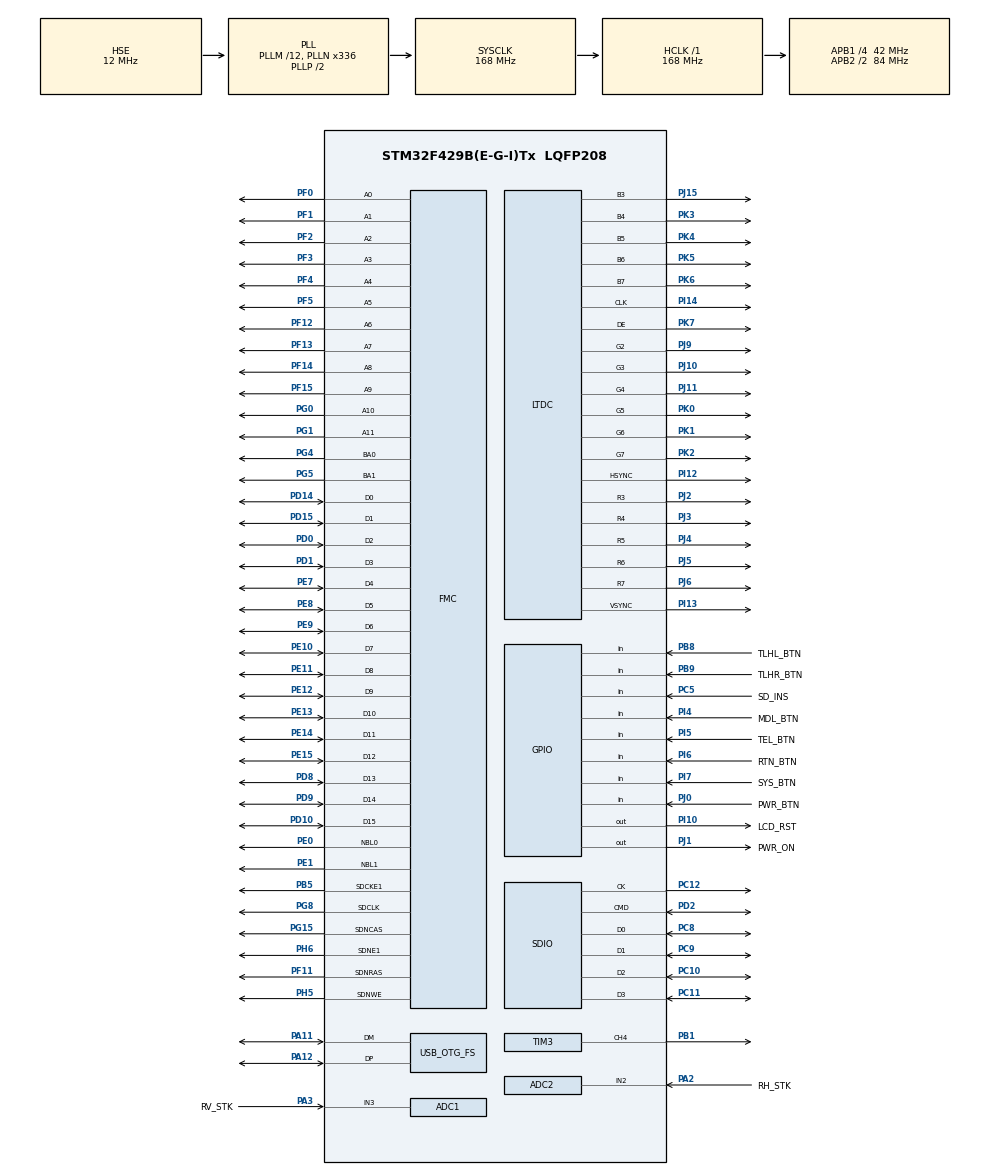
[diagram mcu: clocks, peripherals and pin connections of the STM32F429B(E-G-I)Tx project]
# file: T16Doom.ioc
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ADC1.Channel-0\#ChannelRegularConversion=ADC_CHANNEL_3
ADC1.NbrOfConversion=1
ADC1.NbrOfConversionFlag=1
ADC1.Rank-0\#ChannelRegularConversion=1
ADC1.SamplingTime-0\#ChannelRegularConversion=ADC_SAMPLETIME_3CYCLES
ADC1.master=1
ADC2.Channel-0\#ChannelRegularConversion=ADC_CHANNEL_2
ADC2.NbrOfConversionFlag=1
ADC2.Rank-0\#ChannelRegularConversion=1
ADC2.SamplingTime-0\#ChannelRegularConversion=ADC_SAMPLETIME_3CYCLES
Dma.Request0=SDIO_RX
Dma.Request1=SDIO_TX
Dma.SDIO_RX.0.Direction=DMA_PERIPH_TO_MEMORY
Dma.SDIO_RX.0.FIFOMode=DMA_FIFOMODE_ENABLE
Dma.SDIO_RX.0.FIFOThreshold=DMA_FIFO_THRESHOLD_FULL
Dma.SDIO_RX.0.Instance=DMA2_Stream3
Dma.SDIO_RX.0.MemBurst=DMA_MBURST_INC4
Dma.SDIO_RX.0.MemDataAlignment=DMA_MDATAALIGN_WORD
Dma.SDIO_RX.0.MemInc=DMA_MINC_ENABLE
Dma.SDIO_RX.0.Mode=DMA_PFCTRL
Dma.SDIO_RX.0.PeriphBurst=DMA_PBURST_INC4
Dma.SDIO_RX.0.PeriphDataAlignment=DMA_PDATAALIGN_WORD
Dma.SDIO_RX.0.PeriphInc=DMA_PINC_DISABLE
Dma.SDIO_RX.0.Priority=DMA_PRIORITY_LOW
Dma.SDIO_TX.1.Direction=DMA_MEMORY_TO_PERIPH
Dma.SDIO_TX.1.FIFOMode=DMA_FIFOMODE_ENABLE
Dma.SDIO_TX.1.FIFOThreshold=DMA_FIFO_THRESHOLD_FULL
Dma.SDIO_TX.1.Instance=DMA2_Stream6
Dma.SDIO_TX.1.MemBurst=DMA_MBURST_INC4
Dma.SDIO_TX.1.MemDataAlignment=DMA_MDATAALIGN_WORD
Dma.SDIO_TX.1.MemInc=DMA_MINC_ENABLE
Dma.SDIO_TX.1.Mode=DMA_PFCTRL
Dma.SDIO_TX.1.PeriphBurst=DMA_PBURST_INC4
Dma.SDIO_TX.1.PeriphDataAlignment=DMA_PDATAALIGN_WORD
Dma.SDIO_TX.1.PeriphInc=DMA_PINC_DISABLE
Dma.SDIO_TX.1.Priority=DMA_PRIORITY_LOW
FATFS.BSP.number=1
FATFS.USE_DMA_CODE_SD=1
FATFS._MAX_SS=4096
FATFS0.BSP.STBoard=false
FATFS0.BSP.api=Unknown
FATFS0.BSP.i2caddr=0
FATFS0.BSP.instance=PC5
FATFS0.BSP.ip=GPIO
FATFS0.BSP.mode=Input
FATFS0.BSP.name=Detect_SDIO
FATFS0.BSP.solution=PC5
FMC.CASLatency1=FMC_SDRAM_CAS_LATENCY_3
FMC.ExitSelfRefreshDelay1=7
FMC.LoadToActiveDelay1=2
FMC.RCDDelay1=2
FMC.RPDelay1=2
FMC.RPDelay2=2
FMC.RowCycleDelay1=7
FMC.RowCycleDelay2=7
FMC.SDClockPeriod1=FMC_SDRAM_CLOCK_PERIOD_2
FMC.SDClockPeriod2=FMC_SDRAM_CLOCK_PERIOD_2
FMC.SelfRefreshTime1=4
FMC.WriteRecoveryTime1=3
LTDC.ActiveH=272
LTDC.ActiveW=480
LTDC.Alpha_L0=255
LTDC.Alpha_L1=255
LTDC.BlendingFactor1_L0=LTDC_BLENDING_FACTOR1_CA
LTDC.BlendingFactor1_L1=LTDC_BLENDING_FACTOR1_CA
LTDC.BlendingFactor2_L0=LTDC_BLENDING_FACTOR2_CA
LTDC.BlendingFactor2_L1=LTDC_BLENDING_FACTOR2_CA
LTDC.FBStartAdress_L0=(uint32_t) LCDFrameBuffer
LTDC.HBP=40
LTDC.HFP=3
LTDC.HSync=3
LTDC.ImageHeight_L0=272
LTDC.ImageHeight_L1=272
LTDC.ImageWidth_L0=480
LTDC.ImageWidth_L1=480
LTDC.Layers=0
LTDC.PCPolarity=LTDC_PCPOLARITY_IIPC
LTDC.PixelFormat_L0=LTDC_PIXEL_FORMAT_RGB565
LTDC.VBP=2
LTDC.VFP=2
LTDC.VSync=11
LTDC.WindowX0_L0=0
LTDC.WindowX0_L1=0
LTDC.WindowX1_L0=480
LTDC.WindowX1_L1=480
LTDC.WindowY0_L0=0
LTDC.WindowY0_L1=0
LTDC.WindowY1_L0=272
LTDC.WindowY1_L1=272
Mcu.Family=STM32F4
Mcu.Name=STM32F429B(E-G-I)Tx
Mcu.Package=LQFP208
NVIC.DMA2_Stream3_IRQn=true\:0\:0\:false\:false\:true\:false\:true
NVIC.DMA2_Stream6_IRQn=true\:0\:0\:false\:false\:true\:false\:true
NVIC.OTG_FS_IRQn=true\:0\:0\:false\:false\:true\:false\:true
NVIC.PriorityGroup=NVIC_PRIORITYGROUP_4
NVIC.SDIO_IRQn=true\:0\:0\:false\:false\:true\:true\:true
PA11.Mode=Device_Only
PA11.Signal=USB_OTG_FS_DM
PA12.Mode=Device_Only
PA12.Signal=USB_OTG_FS_DP
PA2.GPIO_Label=RH_STK
PA2.Signal=SharedAnalog_PA2
PA3.GPIO_Label=RV_STK
PA3.Signal=SharedAnalog_PA3
PB1.Signal=S_TIM3_CH4
PB5.Mode=SdramChipSelect2_1
PB5.Signal=FMC_SDCKE1
PB8.GPIO_Label=TLHL_BTN
PB8.GPIO_PuPd=GPIO_PULLUP
PB8.Signal=GPIO_Input
PB9.GPIO_Label=TLHR_BTN
PB9.GPIO_PuPd=GPIO_PULLUP
PB9.Signal=GPIO_Input
PC10.GPIO_PuPd=GPIO_PULLUP
PC10.Mode=SD_4_bits_Wide_bus
PC10.Signal=SDIO_D2
PC11.GPIO_PuPd=GPIO_PULLUP
PC11.Mode=SD_4_bits_Wide_bus
PC11.Signal=SDIO_D3
PC12.Mode=SD_4_bits_Wide_bus
PC12.Signal=SDIO_CK
PC14/OSC32_IN.Mode=LSE-External-Oscillator
PC14/OSC32_IN.Signal=RCC_OSC32_IN
PC15/OSC32_OUT.Mode=LSE-External-Oscillator
PC15/OSC32_OUT.Signal=RCC_OSC32_OUT
PC5.GPIO_Label=SD_INS
PC5.Signal=GPIO_Input
PC8.GPIO_PuPd=GPIO_PULLUP
PC8.Mode=SD_4_bits_Wide_bus
PC8.Signal=SDIO_D0
PC9.GPIO_PuPd=GPIO_PULLUP
PC9.Mode=SD_4_bits_Wide_bus
PC9.Signal=SDIO_D1
PD0.Signal=FMC_D2_DA2
PD1.Signal=FMC_D3_DA3
PD10.Signal=FMC_D15_DA15
PD14.Signal=FMC_D0_DA0
PD15.Signal=FMC_D1_DA1
PD2.GPIO_PuPd=GPIO_PULLUP
PD2.Mode=SD_4_bits_Wide_bus
PD2.Signal=SDIO_CMD
PD8.Signal=FMC_D13_DA13
PD9.Signal=FMC_D14_DA14
PE0.Signal=FMC_NBL0
PE1.Signal=FMC_NBL1
PE10.Signal=FMC_D7_DA7
PE11.Signal=FMC_D8_DA8
PE12.Signal=FMC_D9_DA9
PE13.Signal=FMC_D10_DA10
PE14.Signal=FMC_D11_DA11
PE15.Signal=FMC_D12_DA12
PE7.Signal=FMC_D4_DA4
PE8.Signal=FMC_D5_DA5
PE9.Signal=FMC_D6_DA6
PF0.Signal=FMC_A0
PF1.Signal=FMC_A1
PF11.Signal=FMC_SDNRAS
PF12.Signal=FMC_A6
PF13.Signal=FMC_A7
PF14.Signal=FMC_A8
PF15.Signal=FMC_A9
PF2.Signal=FMC_A2
PF3.Signal=FMC_A3
PF4.Signal=FMC_A4
PF5.Signal=FMC_A5
PG0.Signal=FMC_A10
PG1.Signal=FMC_A11
PG15.Signal=FMC_SDNCAS
PG4.Signal=FMC_A14_BA0
PG5.Signal=FMC_A15_BA1
PG8.Signal=FMC_SDCLK
PH0/OSC_IN.Mode=HSE-External-Oscillator
PH0/OSC_IN.Signal=RCC_OSC_IN
PH1/OSC_OUT.Mode=HSE-External-Oscillator
PH1/OSC_OUT.Signal=RCC_OSC_OUT
PH5.Signal=FMC_SDNWE
PH6.Mode=SdramChipSelect2_1
PH6.Signal=FMC_SDNE1
PI10.GPIO_Label=LCD_RST
PI10.Signal=GPIO_Output
PI12.GPIO_Speed=GPIO_SPEED_FREQ_LOW
PI12.Mode=RGB565
PI12.Signal=LTDC_HSYNC
PI13.GPIO_Speed=GPIO_SPEED_FREQ_LOW
PI13.Mode=RGB565
PI13.Signal=LTDC_VSYNC
PI14.GPIO_Speed=GPIO_SPEED_FREQ_LOW
PI14.Mode=RGB565
PI14.Signal=LTDC_CLK
PI4.GPIO_Label=MDL_BTN
PI4.GPIO_PuPd=GPIO_PULLUP
PI4.Signal=GPIO_Input
PI5.GPIO_Label=TEL_BTN
PI5.GPIO_PuPd=GPIO_PULLUP
PI5.Signal=GPIO_Input
PI6.GPIO_Label=RTN_BTN
PI6.GPIO_PuPd=GPIO_PULLUP
PI6.Signal=GPIO_Input
PI7.GPIO_Label=SYS_BTN
PI7.GPIO_PuPd=GPIO_PULLUP
PI7.Signal=GPIO_Input
PJ0.GPIO_Label=PWR_BTN
PJ0.Signal=GPIO_Input
PJ1.GPIO_Label=PWR_ON
PJ1.Signal=GPIO_Output
PJ10.GPIO_Speed=GPIO_SPEED_FREQ_LOW
PJ10.Mode=RGB565
PJ10.Signal=LTDC_G3
PJ11.GPIO_Speed=GPIO_SPEED_FREQ_LOW
PJ11.Mode=RGB565
PJ11.Signal=LTDC_G4
PJ15.GPIO_Speed=GPIO_SPEED_FREQ_LOW
PJ15.Mode=RGB565
PJ15.Signal=LTDC_B3
PJ2.GPIO_Speed=GPIO_SPEED_FREQ_LOW
PJ2.Mode=RGB565
PJ2.Signal=LTDC_R3
PJ3.GPIO_Speed=GPIO_SPEED_FREQ_LOW
PJ3.Mode=RGB565
PJ3.Signal=LTDC_R4
PJ4.GPIO_Speed=GPIO_SPEED_FREQ_LOW
PJ4.Mode=RGB565
PJ4.Signal=LTDC_R5
PJ5.GPIO_Speed=GPIO_SPEED_FREQ_LOW
PJ5.Mode=RGB565
PJ5.Signal=LTDC_R6
PJ6.GPIO_Speed=GPIO_SPEED_FREQ_LOW
PJ6.Mode=RGB565
PJ6.Signal=LTDC_R7
PJ9.GPIO_Speed=GPIO_SPEED_FREQ_LOW
PJ9.Mode=RGB565
PJ9.Signal=LTDC_G2
PK0.GPIO_Speed=GPIO_SPEED_FREQ_LOW
PK0.Mode=RGB565
PK0.Signal=LTDC_G5
PK1.GPIO_Speed=GPIO_SPEED_FREQ_LOW
PK1.Mode=RGB565
PK1.Signal=LTDC_G6
PK2.GPIO_Speed=GPIO_SPEED_FREQ_LOW
PK2.Mode=RGB565
PK2.Signal=LTDC_G7
PK3.GPIO_Speed=GPIO_SPEED_FREQ_LOW
PK3.Mode=RGB565
PK3.Signal=LTDC_B4
PK4.GPIO_Speed=GPIO_SPEED_FREQ_LOW
PK4.Mode=RGB565
PK4.Signal=LTDC_B5
PK5.GPIO_Speed=GPIO_SPEED_FREQ_LOW
PK5.Mode=RGB565
PK5.Signal=LTDC_B6
PK6.GPIO_Speed=GPIO_SPEED_FREQ_LOW
PK6.Mode=RGB565
PK6.Signal=LTDC_B7
PK7.GPIO_Speed=GPIO_SPEED_FREQ_LOW
PK7.Mode=RGB565
PK7.Signal=LTDC_DE
ProjectManager.HeapSize=0x200
ProjectManager.StackSize=0x400
ProjectManager.TargetToolchain=Makefile
RCC.48MHZClocksFreq_Value=48000000
RCC.AHBFreq_Value=168000000
RCC.APB1CLKDivider=RCC_HCLK_DIV4
RCC.APB1Freq_Value=42000000
RCC.APB1TimFreq_Value=84000000
RCC.APB2CLKDivider=RCC_HCLK_DIV2
RCC.APB2Freq_Value=84000000
RCC.APB2TimFreq_Value=168000000
RCC.CortexFreq_Value=168000000
RCC.HCLKFreq_Value=168000000
RCC.HSE_VALUE=12000000
RCC.HSI_VALUE=16000000
RCC.PLLM=12
RCC.PLLN=336
RCC.PLLQ=7
RCC.PLLSAIDivR=RCC_PLLSAIDIVR_4
RCC.PLLSAIN=192
RCC.PLLSAIR=3
RCC.SYSCLKFreq_VALUE=168000000
RCC.SYSCLKSource=RCC_SYSCLKSOURCE_PLLCLK
RCC.VCOOutputFreq_Value=336000000
SDIO.ClockDiv=0
SH.FMC_A0.0=FMC_A0,12b-sda1
SH.FMC_A1.0=FMC_A1,12b-sda1
SH.FMC_A10.0=FMC_A10,12b-sda1
SH.FMC_A11.0=FMC_A11,12b-sda1
SH.FMC_A14_BA0.0=FMC_BA0,FourSdramBanks1
SH.FMC_A15_BA1.0=FMC_BA1,FourSdramBanks1
SH.FMC_A2.0=FMC_A2,12b-sda1
SH.FMC_A3.0=FMC_A3,12b-sda1
SH.FMC_A4.0=FMC_A4,12b-sda1
SH.FMC_A5.0=FMC_A5,12b-sda1
SH.FMC_A6.0=FMC_A6,12b-sda1
SH.FMC_A7.0=FMC_A7,12b-sda1
SH.FMC_A8.0=FMC_A8,12b-sda1
SH.FMC_A9.0=FMC_A9,12b-sda1
SH.FMC_D0_DA0.0=FMC_D0,sd-16b-d1
SH.FMC_D10_DA10.0=FMC_D10,sd-16b-d1
SH.FMC_D11_DA11.0=FMC_D11,sd-16b-d1
SH.FMC_D12_DA12.0=FMC_D12,sd-16b-d1
SH.FMC_D13_DA13.0=FMC_D13,sd-16b-d1
SH.FMC_D14_DA14.0=FMC_D14,sd-16b-d1
SH.FMC_D15_DA15.0=FMC_D15,sd-16b-d1
SH.FMC_D1_DA1.0=FMC_D1,sd-16b-d1
SH.FMC_D2_DA2.0=FMC_D2,sd-16b-d1
SH.FMC_D3_DA3.0=FMC_D3,sd-16b-d1
SH.FMC_D4_DA4.0=FMC_D4,sd-16b-d1
SH.FMC_D5_DA5.0=FMC_D5,sd-16b-d1
SH.FMC_D6_DA6.0=FMC_D6,sd-16b-d1
SH.FMC_D7_DA7.0=FMC_D7,sd-16b-d1
SH.FMC_D8_DA8.0=FMC_D8,sd-16b-d1
SH.FMC_D9_DA9.0=FMC_D9,sd-16b-d1
SH.FMC_NBL0.0=FMC_NBL0,Sd2ByteEnable1
SH.FMC_NBL1.0=FMC_NBL1,Sd2ByteEnable1
SH.FMC_SDCLK.0=FMC_SDCLK,12b-sda1
SH.FMC_SDNCAS.0=FMC_SDNCAS,12b-sda1
SH.FMC_SDNRAS.0=FMC_SDNRAS,12b-sda1
SH.FMC_SDNWE.0=FMC_SDNWE,12b-sda1
SH.S_TIM3_CH4.0=TIM3_CH4,PWM Generation4 CH4
SH.SharedAnalog_PA2.0=GPIO_Analog
SH.SharedAnalog_PA2.1=ADC2_IN2,IN2
SH.SharedAnalog_PA3.0=GPIO_Analog
SH.SharedAnalog_PA3.1=ADC1_IN3,IN3
TIM3.Channel-PWM\ Generation4\ CH4=TIM_CHANNEL_4
TIM3.OCMode_PWM-PWM\ Generation4\ CH4=TIM_OCMODE_PWM1
TIM3.OCPolarity_4=TIM_OCPOLARITY_HIGH
TIM3.Period=8399
TIM3.Pulse-PWM\ Generation4\ CH4=4199
USB_DEVICE.CLASS_NAME_FS=CDC
USB_DEVICE.VirtualMode-CDC_FS=Cdc
USB_DEVICE.VirtualModeFS=Cdc_FS
USB_OTG_FS.VirtualMode=Device_Only
VP_FATFS_VS_SDIO.Mode=SDIO
VP_USB_DEVICE_VS_USB_DEVICE_CDC_FS.Mode=CDC_FS
board=custom

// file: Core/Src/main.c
/* USER CODE BEGIN Header */
/**
  ******************************************************************************
  * @file           : main.c
  * @brief          : Main program body
  ******************************************************************************
  * @attention
  *
  * Copyright (c) 2021 STMicroelectronics.
  * All rights reserved.
  *
  * This software is licensed under terms that can be found in the LICENSE file
  * in the root directory of this software component.
  * If no LICENSE file comes with this software, it is provided AS-IS.
  *
  ******************************************************************************
  */
/* USER CODE END Header */
#include "main.h"
#include "adc.h"
#include "dma.h"
#include "fatfs.h"
#include "ltdc.h"
#include "sdio.h"
#include "tim.h"
#include "usb_device.h"
#include "gpio.h"
#include "fmc.h"

/* USER CODE BEGIN Includes */
#include "../../../umm_malloc/umm_malloc.h"
/* USER CODE END Includes */

/* USER CODE BEGIN PD */
#define __SDRAM   __attribute__((section(".sdram"), aligned(4)))
/* USER CODE END PD */

/* USER CODE BEGIN PV */
static FATFS FatFs = {0}; 	//Fatfs handle
/* USER CODE END PV */

void SystemClock_Config(void);

int main(void)
{

  /* MCU Configuration--------------------------------------------------------*/

  /* Reset of all peripherals, Initializes the Flash interface and the Systick. */
  HAL_Init();

  /* Configure the system clock */
  SystemClock_Config();

  /* Initialize all configured peripherals */
  MX_GPIO_Init();
  MX_ADC1_Init();
  MX_ADC2_Init();
  MX_FMC_Init();
  MX_USB_DEVICE_Init();
  MX_SDIO_SD_Init();
  MX_FATFS_Init();
  MX_LTDC_Init();
  MX_DMA_Init();
  MX_TIM3_Init();
  /* USER CODE BEGIN 2 */
  HAL_TIM_PWM_Start(&htim3, TIM_CHANNEL_4);
  //Keep Power On
  HAL_GPIO_WritePin(PWR_ON_GPIO_Port, PWR_ON_Pin, GPIO_PIN_SET);

  //Open the file system
  FRESULT fres = f_mount(&FatFs, "", 1); //1=mount now

  //CDC_Transmit_FS(buffer, sizeof(buffer));

  if (fres != FR_OK) {
    HAL_GPIO_WritePin(GPIOJ, GPIO_PIN_1, GPIO_PIN_RESET);
    while (1) {};
  }

  umm_init_heap((void*) 0xD004A400, 0x78000 - 1);

  atexit(HAL_NVIC_SystemReset);
  at_quick_exit(HAL_NVIC_SystemReset);

  extern void doom_main(int argc, char* argv[]);

  char* argv[] = {"doom", "-iwad", "doom1.wad", NULL};
  int argc = sizeof(argv) / sizeof(argv[0]) - 1;

  doom_main(argc, argv);

  /* USER CODE END 2 */

  /* Infinite loop */
  while (1)
  {

  }
}

void SystemClock_Config(void)
{
  RCC_OscInitTypeDef RCC_OscInitStruct = {0};
  RCC_ClkInitTypeDef RCC_ClkInitStruct = {0};

  /** Configure the main internal regulator output voltage
  */
  __HAL_RCC_PWR_CLK_ENABLE();
  __HAL_PWR_VOLTAGESCALING_CONFIG(PWR_REGULATOR_VOLTAGE_SCALE1);
  /** Initializes the RCC Oscillators according to the specified parameters
  * in the RCC_OscInitTypeDef structure.
  */
  RCC_OscInitStruct.OscillatorType = RCC_OSCILLATORTYPE_HSE;
  RCC_OscInitStruct.HSEState = RCC_HSE_ON;
  RCC_OscInitStruct.PLL.PLLState = RCC_PLL_ON;
  RCC_OscInitStruct.PLL.PLLSource = RCC_PLLSOURCE_HSE;
  RCC_OscInitStruct.PLL.PLLM = 12;
  RCC_OscInitStruct.PLL.PLLN = 336;
  RCC_OscInitStruct.PLL.PLLP = RCC_PLLP_DIV2;
  RCC_OscInitStruct.PLL.PLLQ = 7;
  if (HAL_RCC_OscConfig(&RCC_OscInitStruct) != HAL_OK)
  {
    Error_Handler();
  }
  /** Initializes the CPU, AHB and APB buses clocks
  */
  RCC_ClkInitStruct.ClockType = RCC_CLOCKTYPE_HCLK|RCC_CLOCKTYPE_SYSCLK
                              |RCC_CLOCKTYPE_PCLK1|RCC_CLOCKTYPE_PCLK2;
  RCC_ClkInitStruct.SYSCLKSource = RCC_SYSCLKSOURCE_PLLCLK;
  RCC_ClkInitStruct.AHBCLKDivider = RCC_SYSCLK_DIV1;
  RCC_ClkInitStruct.APB1CLKDivider = RCC_HCLK_DIV4;
  RCC_ClkInitStruct.APB2CLKDivider = RCC_HCLK_DIV2;

  if (HAL_RCC_ClockConfig(&RCC_ClkInitStruct, FLASH_LATENCY_5) != HAL_OK)
  {
    Error_Handler();
  }
}

void Error_Handler(void)
{
  __disable_irq();
  while (1)
  {
  }
}
